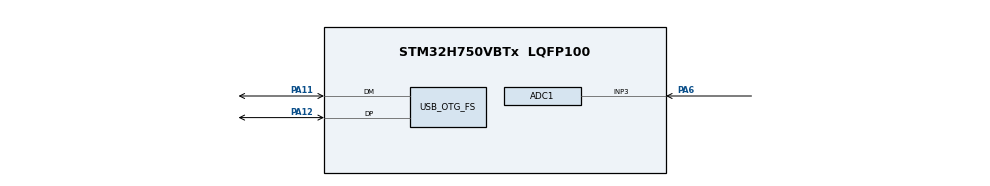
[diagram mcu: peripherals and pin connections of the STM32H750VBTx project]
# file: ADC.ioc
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ADC1.Channel-1\#ChannelRegularConversion=ADC_CHANNEL_3
ADC1.NbrOfConversionFlag=1
ADC1.OffsetNumber-1\#ChannelRegularConversion=ADC_OFFSET_NONE
ADC1.OffsetSignedSaturation-1\#ChannelRegularConversion=DISABLE
ADC1.Rank-1\#ChannelRegularConversion=1
ADC1.SamplingTime-1\#ChannelRegularConversion=ADC_SAMPLETIME_810CYCLES_5
ADC1.master=1
Mcu.Family=STM32H7
Mcu.Name=STM32H750VBTx
Mcu.Package=LQFP100
NVIC.OTG_FS_IRQn=true\:0\:0\:false\:false\:true\:false\:true\:true
NVIC.PriorityGroup=NVIC_PRIORITYGROUP_4
PA11.Mode=Device_Only
PA11.Signal=USB_OTG_FS_DM
PA12.Mode=Device_Only
PA12.Signal=USB_OTG_FS_DP
PA6.Signal=ADCx_INP3
ProjectManager.HeapSize=0x200
ProjectManager.StackSize=0x400
ProjectManager.TargetToolchain=STM32CubeIDE
RCC.ADCCLockSelection=RCC_ADCCLKSOURCE_CLKP
RCC.ADCFreq_Value=64000000
RCC.APB1Freq_Value=64000000
RCC.APB2Freq_Value=64000000
RCC.APB3Freq_Value=64000000
RCC.APB4Freq_Value=64000000
RCC.CortexFreq_Value=64000000
RCC.DIVM1=4
RCC.DIVN1=9
RCC.DIVQ1=3
RCC.HCLKFreq_Value=64000000
RCC.PLLFRACN=0
RCC.SYSCLKFreq_VALUE=64000000
RCC.USBCLockSelection=RCC_USBCLKSOURCE_HSI48
RCC.USBFreq_Value=48000000
SH.ADCx_INP3.0=ADC1_INP3,IN3-Single-Ended
USB_DEVICE.CLASS_NAME_FS=CDC
USB_DEVICE.VirtualMode-CDC_FS=Cdc
USB_DEVICE.VirtualModeFS=Cdc_FS
USB_OTG_FS.VirtualMode=Device_Only
VP_MEMORYMAP_VS_MEMORYMAP.Mode=CurAppReg
VP_USB_DEVICE_VS_USB_DEVICE_CDC_FS.Mode=CDC_FS
board=custom

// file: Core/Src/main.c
/* USER CODE BEGIN Header */
/**
  ******************************************************************************
  * @file           : main.c
  * @brief          : Main program body
  ******************************************************************************
  * @attention
  *
  * Copyright (c) 2025 STMicroelectronics.
  * All rights reserved.
  *
  * This software is licensed under terms that can be found in the LICENSE file
  * in the root directory of this software component.
  * If no LICENSE file comes with this software, it is provided AS-IS.
  *
  ******************************************************************************
  */
/* USER CODE END Header */
#include "main.h"
#include "usb_device.h"
#include "usbd_cdc_if.h"
#include <stdio.h>

/* USER CODE BEGIN PD */
#define AAS 32
/* USER CODE END PD */

ADC_HandleTypeDef hadc1;

void SystemClock_Config(void);
void PeriphCommonClock_Config(void);
static void MX_GPIO_Init(void);
static void MX_ADC1_Init(void);
uint16_t ReadADC(void);
void USBDataSend(void);

/* USER CODE BEGIN 0 */

uint16_t ReadADC(void)
{
    uint32_t sum = 0;

    for (uint16_t i = 0; i < AAS; i++)
    {
        HAL_ADC_Start(&hadc1);

        HAL_ADC_PollForConversion(&hadc1, HAL_MAX_DELAY);

        uint16_t value = HAL_ADC_GetValue(&hadc1);

        HAL_ADC_Stop(&hadc1);

        sum += value;
    }

    return (uint16_t)(sum / AAS);
}

void USBDataSend(void)
{
	uint16_t avg = ReadADC();

	float voltage = 3.3f * ((float)avg / 64320.0f);

	char msg[64];

	int len = snprintf(msg, sizeof(msg), "avg=%u; voltage=%.3f V\r\n", avg , voltage);

	CDC_Transmit_FS((uint8_t*) msg, len);

}

/* USER CODE END 0 */

int main(void)
{

  /* MCU Configuration--------------------------------------------------------*/

  /* Reset of all peripherals, Initializes the Flash interface and the Systick. */
  HAL_Init();

  /* Configure the system clock */
  SystemClock_Config();

  /* Configure the peripherals common clocks */
  PeriphCommonClock_Config();

  /* Initialize all configured peripherals */
  MX_GPIO_Init();
  MX_ADC1_Init();
  MX_USB_DEVICE_Init();
  /* USER CODE BEGIN 2 */
  HAL_ADCEx_Calibration_Start(&hadc1, ADC_CALIB_OFFSET, ADC_SINGLE_ENDED);
  /* USER CODE END 2 */

  /* Infinite loop */
  while (1)
  {

    /* USER CODE BEGIN 3 */
	  USBDataSend();
	  HAL_Delay(100);  // wait
  }
  /* USER CODE END 3 */
}

void SystemClock_Config(void)
{
  RCC_OscInitTypeDef RCC_OscInitStruct = {0};
  RCC_ClkInitTypeDef RCC_ClkInitStruct = {0};

  /** Supply configuration update enable
  */
  HAL_PWREx_ConfigSupply(PWR_LDO_SUPPLY);

  /** Configure the main internal regulator output voltage
  */
  __HAL_PWR_VOLTAGESCALING_CONFIG(PWR_REGULATOR_VOLTAGE_SCALE3);

  while(!__HAL_PWR_GET_FLAG(PWR_FLAG_VOSRDY)) {}

  /** Initializes the RCC Oscillators according to the specified parameters
  * in the RCC_OscInitTypeDef structure.
  */
  RCC_OscInitStruct.OscillatorType = RCC_OSCILLATORTYPE_HSI48|RCC_OSCILLATORTYPE_HSI;
  RCC_OscInitStruct.HSIState = RCC_HSI_DIV1;
  RCC_OscInitStruct.HSICalibrationValue = RCC_HSICALIBRATION_DEFAULT;
  RCC_OscInitStruct.HSI48State = RCC_HSI48_ON;
  RCC_OscInitStruct.PLL.PLLState = RCC_PLL_NONE;
  if (HAL_RCC_OscConfig(&RCC_OscInitStruct) != HAL_OK)
  {
    Error_Handler();
  }

  /** Initializes the CPU, AHB and APB buses clocks
  */
  RCC_ClkInitStruct.ClockType = RCC_CLOCKTYPE_HCLK|RCC_CLOCKTYPE_SYSCLK
                              |RCC_CLOCKTYPE_PCLK1|RCC_CLOCKTYPE_PCLK2
                              |RCC_CLOCKTYPE_D3PCLK1|RCC_CLOCKTYPE_D1PCLK1;
  RCC_ClkInitStruct.SYSCLKSource = RCC_SYSCLKSOURCE_HSI;
  RCC_ClkInitStruct.SYSCLKDivider = RCC_SYSCLK_DIV1;
  RCC_ClkInitStruct.AHBCLKDivider = RCC_HCLK_DIV1;
  RCC_ClkInitStruct.APB3CLKDivider = RCC_APB3_DIV1;
  RCC_ClkInitStruct.APB1CLKDivider = RCC_APB1_DIV1;
  RCC_ClkInitStruct.APB2CLKDivider = RCC_APB2_DIV1;
  RCC_ClkInitStruct.APB4CLKDivider = RCC_APB4_DIV1;

  if (HAL_RCC_ClockConfig(&RCC_ClkInitStruct, FLASH_LATENCY_1) != HAL_OK)
  {
    Error_Handler();
  }
}

void PeriphCommonClock_Config(void)
{
  RCC_PeriphCLKInitTypeDef PeriphClkInitStruct = {0};

  /** Initializes the peripherals clock
  */
  PeriphClkInitStruct.PeriphClockSelection = RCC_PERIPHCLK_CKPER;
  PeriphClkInitStruct.CkperClockSelection = RCC_CLKPSOURCE_HSI;
  if (HAL_RCCEx_PeriphCLKConfig(&PeriphClkInitStruct) != HAL_OK)
  {
    Error_Handler();
  }
}

static void MX_ADC1_Init(void)
{

  ADC_MultiModeTypeDef multimode = {0};
  ADC_ChannelConfTypeDef sConfig = {0};

  /** Common config
  */
  hadc1.Instance = ADC1;
  hadc1.Init.ClockPrescaler = ADC_CLOCK_ASYNC_DIV2;
  hadc1.Init.Resolution = ADC_RESOLUTION_16B;
  hadc1.Init.ScanConvMode = ADC_SCAN_DISABLE;
  hadc1.Init.EOCSelection = ADC_EOC_SINGLE_CONV;
  hadc1.Init.LowPowerAutoWait = DISABLE;
  hadc1.Init.ContinuousConvMode = DISABLE;
  hadc1.Init.NbrOfConversion = 1;
  hadc1.Init.DiscontinuousConvMode = DISABLE;
  hadc1.Init.ExternalTrigConv = ADC_SOFTWARE_START;
  hadc1.Init.ExternalTrigConvEdge = ADC_EXTERNALTRIGCONVEDGE_NONE;
  hadc1.Init.ConversionDataManagement = ADC_CONVERSIONDATA_DR;
  hadc1.Init.Overrun = ADC_OVR_DATA_PRESERVED;
  hadc1.Init.LeftBitShift = ADC_LEFTBITSHIFT_NONE;
  hadc1.Init.OversamplingMode = DISABLE;
  hadc1.Init.Oversampling.Ratio = 1;
  if (HAL_ADC_Init(&hadc1) != HAL_OK)
  {
    Error_Handler();
  }

  /** Configure the ADC multi-mode
  */
  multimode.Mode = ADC_MODE_INDEPENDENT;
  if (HAL_ADCEx_MultiModeConfigChannel(&hadc1, &multimode) != HAL_OK)
  {
    Error_Handler();
  }

  /** Configure Regular Channel
  */
  sConfig.Channel = ADC_CHANNEL_3;
  sConfig.Rank = ADC_REGULAR_RANK_1;
  sConfig.SamplingTime = ADC_SAMPLETIME_810CYCLES_5;
  sConfig.SingleDiff = ADC_SINGLE_ENDED;
  sConfig.OffsetNumber = ADC_OFFSET_NONE;
  sConfig.Offset = 0;
  sConfig.OffsetSignedSaturation = DISABLE;
  if (HAL_ADC_ConfigChannel(&hadc1, &sConfig) != HAL_OK)
  {
    Error_Handler();
  }

}

static void MX_GPIO_Init(void)
{

  /* GPIO Ports Clock Enable */
  __HAL_RCC_GPIOA_CLK_ENABLE();

}

void Error_Handler(void)
{
  __disable_irq();
  while (1)
  {
  }
}
